# RK3399-AP register map
File version: 1
CPU: CA7 r0p1, little endian, MPU, FPU, I-cache, D-cache, VTOR, 4 interrupt priority bits, 32 interrupts
Registers are 32-bit, read-write, reset 0x0 unless marked. A register's access mark holds for its fields unless they carry their own. Offsets are from the block's base; [hi:lo] are bit positions; {n}, {i} and the like mark numbered series.

## CRU (part 2 of 3)
Base 0xFF760000
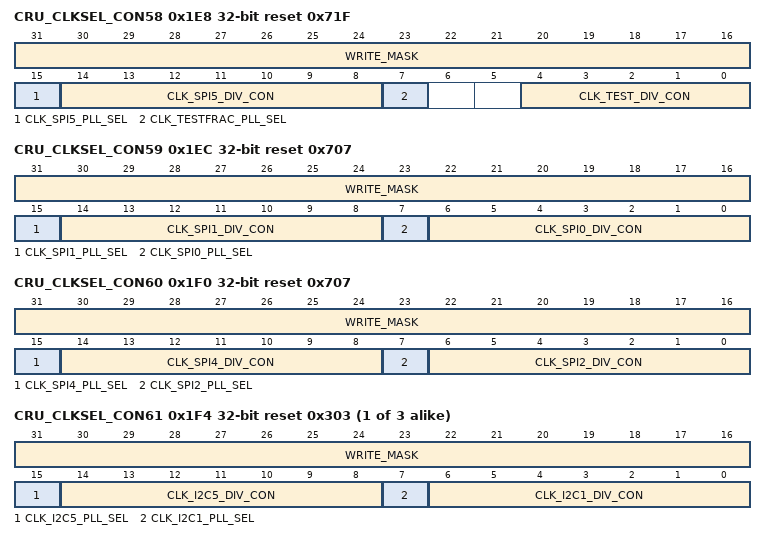
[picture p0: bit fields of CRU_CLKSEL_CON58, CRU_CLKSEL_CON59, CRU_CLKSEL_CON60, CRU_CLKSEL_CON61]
0x1E8 CRU_CLKSEL_CON58 access per field reset 0x71F — Internal clock select and divide register58
  [31:16] WRITE_MASK wo — write mask bits When every bit HIGH, enable the writing corresponding bit When every bit LOW, don't care the writing corresponding bit
  [15] CLK_SPI5_PLL_SEL rw — clk_spi5 clock source select control register 1'b0:CPLL 1'b1:GPLL
  [14:8] CLK_SPI5_DIV_CON rw — spi5 divider control register clk=clk_src/(div_con+1)
  [7] CLK_TESTFRAC_PLL_SEL rw — clk_frac clock source select control register 1'b0:CPLL 1'b1:GPLL
  [4:0] CLK_TEST_DIV_CON rw — test divider control register clk=clk_src/(div_con+1)
0x1EC CRU_CLKSEL_CON59 access per field reset 0x707 — Internal clock select and divide register59
  [31:16] WRITE_MASK wo — write mask bits When every bit HIGH, enable the writing corresponding bit When every bit LOW, don't care the writing corresponding bit
  [15] CLK_SPI1_PLL_SEL rw — clk_spi1 clock source select control register 1'b0:CPLL 1'b1:GPLL
  [14:8] CLK_SPI1_DIV_CON rw — spi1 divider control register clk=clk_src/(div_con+1)
  [7] CLK_SPI0_PLL_SEL rw — clk_spi0 clock source select control register 1'b0:CPLL 1'b1:GPLL
  [6:0] CLK_SPI0_DIV_CON rw — spi0 divider control register clk=clk_src/(div_con+1)
0x1F0 CRU_CLKSEL_CON60 access per field reset 0x707 — Internal clock select and divide register60
  [31:16] WRITE_MASK wo — write mask bits When every bit HIGH, enable the writing corresponding bit When every bit LOW, don't care the writing corresponding bit
  [15] CLK_SPI4_PLL_SEL rw — clk_spi4 clock source select control register 1'b0:CPLL 1'b1:GPLL
  [14:8] CLK_SPI4_DIV_CON rw — spi4 divider control register clk=clk_src/(div_con+1)
  [7] CLK_SPI2_PLL_SEL rw — clk_spi2 clock source select control register 1'b0:CPLL 1'b1:GPLL
  [6:0] CLK_SPI2_DIV_CON rw — spi2 divider control register clk=clk_src/(div_con+1)
{0x100+4i} CRU_CLKSEL_CON{i} access per field reset 0x303 (i=61..63) — Internal clock select and divide register{i}
  [31:16] WRITE_MASK wo — write mask bits When every bit HIGH, enable the writing corresponding bit When every bit LOW, don't care the writing corresponding bit
  [15] CLK_I2C{i-56}_PLL_SEL rw — clk_i2c{i-56} clock source select control register 1'b0:CPLL 1'b1:GPLL
  [14:8] CLK_I2C{i-56}_DIV_CON rw — i2c{i-56} divider control register clk=clk_src/(div_con+1)
  [7] CLK_I2C{i-60}_PLL_SEL rw — clk_i2c{i-60} clock source select control register 1'b0:CPLL 1'b1:GPLL
  [6:0] CLK_I2C{i-60}_DIV_CON rw — i2c{i-60} divider control register clk=clk_src/(div_con+1)
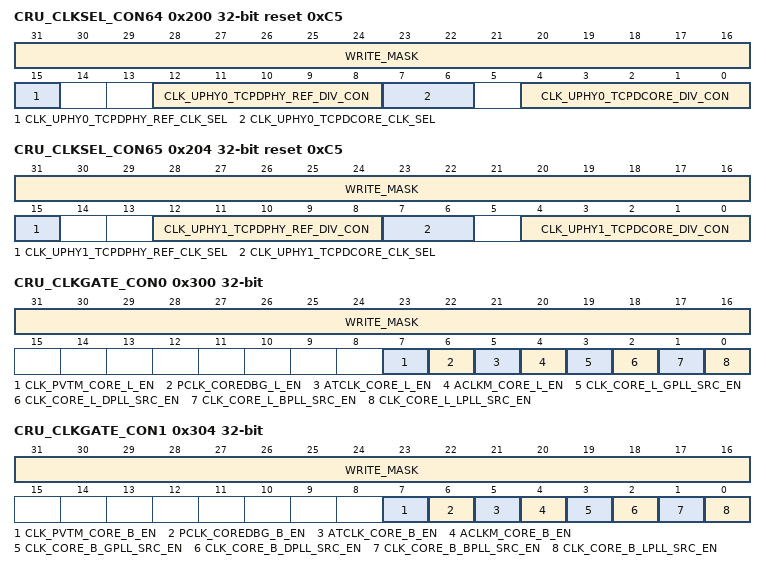
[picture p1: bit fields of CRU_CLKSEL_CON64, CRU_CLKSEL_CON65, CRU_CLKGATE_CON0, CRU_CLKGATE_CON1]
0x200 CRU_CLKSEL_CON64 access per field reset 0xC5 — Internal clock select and divide register64
  [31:16] WRITE_MASK wo — write mask bits When every bit HIGH, enable the writing corresponding bit When every bit LOW, don't care the writing corresponding bit
  [15] CLK_UPHY0_TCPDPHY_REF_CLK_SEL rw — clk_uphy0_tcpdphy_ref clock select control register 1'b0:xin_24m 1'b1:clk_32k
  [12:8] CLK_UPHY0_TCPDPHY_REF_DIV_CON rw — clk_uphy0_tcpdphy_ref divider control register clk=clk_src/(div_con+1)
  [7:6] CLK_UPHY0_TCPDCORE_CLK_SEL rw — clk_uphy0_tcpdcore clock select control register 2'b00:xin_24m 2'b01:clk_32k 2'b10:cpll 2'b11:gpll
  [4:0] CLK_UPHY0_TCPDCORE_DIV_CON rw — clk_uphy0_tcpdcore divider control register clk=clk_src/(div_con+1)
0x204 CRU_CLKSEL_CON65 access per field reset 0xC5 — Internal clock select and divide register65
  [31:16] WRITE_MASK wo — write mask bits When every bit HIGH, enable the writing corresponding bit When every bit LOW, don't care the writing corresponding bit
  [15] CLK_UPHY1_TCPDPHY_REF_CLK_SEL rw — clk_uphy1_tcpdphy_ref clock select control register 1'b0:xin_24m 1'b1:clk_32k
  [12:8] CLK_UPHY1_TCPDPHY_REF_DIV_CON rw — clk_uphy1_tcpdphy_ref divider control register clk=clk_src/(div_con+1)
  [7:6] CLK_UPHY1_TCPDCORE_CLK_SEL rw — clk_uphy1_tcpdcore clock select control register 2'b00:xin_24m 2'b01:clk_32k 2'b10:cpll 2'b11:gpll
  [4:0] CLK_UPHY1_TCPDCORE_DIV_CON rw — clk_uphy1_tcpdcore divider control register clk=clk_src/(div_con+1)
{0x100+4i} CRU_CLKSEL_CON{i} reset 0xBB8EA60 (i=96..98) — Internal clock select and divide register{i-16}
  [31:0] CLK_I2S{i-96}_FRAC_DIV_CON — clk_i2s{i-96}_frac divider control register Fout = Fsrc*numerator/denominator High 16-bit for numerator Low 16-bit for denominator
0x28C CRU_CLKSEL_CON99 reset 0xBB8EA60 — Internal clock select and divide register83
  [31:0] CLK_SPDIF_8CH_FRAC_DIV_CON — spdif_8ch_frac divider control register Fout = Fsrc*numerator/denominator High 16-bit for numerator Low 16-bit for denominator
{0x100+4i} CRU_CLKSEL_CON{i} reset 0xBB8EA60 (i=100..103) — Internal clock select and divide register{i-16}
  [31:0] CLK_UART{i-100}_FRAC_DIV_CON — uart{i-100}_frac divider control register Fout = Fsrc*numerator/denominator High 16-bit for numerator Low 16-bit for denominator
0x2A4 CRU_CLKSEL_CON105 reset 0xBB8EA60 — Internal clock select and divide register89
  [31:0] CLK_TESTFRAC_FRAC_DIV_CON — clk_testfrac frac divider control register Fout = Fsrc*numerator/denominator High 16-bit for numerator Low 16-bit for denominator
0x2A8 CRU_CLKSEL_CON106 reset 0xBB8EA60 — Internal clock select and divide register90
  [31:0] DCLK_VOP0_FRAC_DIV_CON — dclk_vop0_frac divider control register Fout = Fsrc*numerator/denominator High 16-bit for numerator Low 16-bit for denominator
0x2AC CRU_CLKSEL_CON107 reset 0xBB8EA60 — Internal clock select and divide register91
  [31:0] DCLK_VOP1_FRAC_DIV_CON — dclk_vop1_frac divider control register Fout = Fsrc*numerator/denominator High 16-bit for numerator Low 16-bit for denominator
0x300 CRU_CLKGATE_CON0 access per field — Internal clock gating register0
  [31:16] WRITE_MASK wo — write mask bits When every bit HIGH, enable the writing corresponding bit When every bit LOW, don't care the writing corresponding bit
  [7] CLK_PVTM_CORE_L_EN rw — clk_pvtm_core_l clock disable bit When HIGH, disable clock
  [6] PCLK_COREDBG_L_EN rw — pclk_coredbg_l clock disable bit When HIGH, disable clock
  [5] ATCLK_CORE_L_EN rw — atclk_core_l clock disable bit When HIGH, disable clock
  [4] ACLKM_CORE_L_EN rw — aclkm_core_l clock disable bit When HIGH, disable clock
  [3] CLK_CORE_L_GPLL_SRC_EN rw — clk_core_l_gpll clock disable bit When HIGH, disable clock
  [2] CLK_CORE_L_DPLL_SRC_EN rw — clk_core_l_dpll clock disable bit When HIGH, disable clock
  [1] CLK_CORE_L_BPLL_SRC_EN rw — clk_core_l_bpll clock disable bit When HIGH, disable clock
  [0] CLK_CORE_L_LPLL_SRC_EN rw — clk_core_l_lpll clock disable bit When HIGH, disable clock
0x304 CRU_CLKGATE_CON1 access per field — Internal clock gating register1
  [31:16] WRITE_MASK wo — write mask bits When every bit HIGH, enable the writing corresponding bit When every bit LOW, don't care the writing corresponding bit
  [7] CLK_PVTM_CORE_B_EN rw — clk_pvtm_core_b clock disable bit When HIGH, disable clock
  [6] PCLK_COREDBG_B_EN rw — pclk_coredbg_b clock disable bit When HIGH, disable clock
  [5] ATCLK_CORE_B_EN rw — atclk_core_b clock disable bit When HIGH, disable clock
  [4] ACLKM_CORE_B_EN rw — aclkm_core_b clock disable bit When HIGH, disable clock
  [3] CLK_CORE_B_GPLL_SRC_EN rw — clk_core_b_gpll clock disable bit When HIGH, disable clock
  [2] CLK_CORE_B_DPLL_SRC_EN rw — clk_core_b_dpll clock disable bit When HIGH, disable clock
  [1] CLK_CORE_B_BPLL_SRC_EN rw — clk_core_b_bpll clock disable bit When HIGH, disable clock
  [0] CLK_CORE_B_LPLL_SRC_EN rw — clk_core_b_lpll clock disable bit When HIGH, disable clock
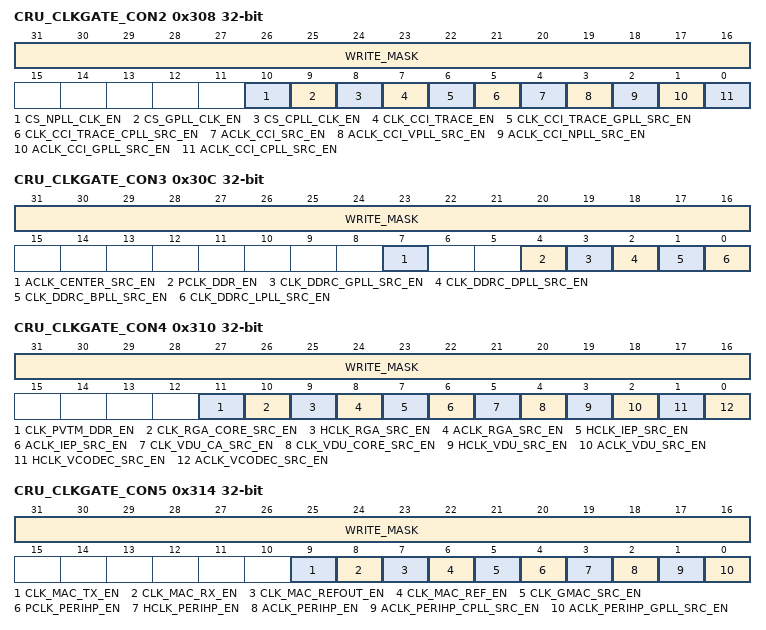
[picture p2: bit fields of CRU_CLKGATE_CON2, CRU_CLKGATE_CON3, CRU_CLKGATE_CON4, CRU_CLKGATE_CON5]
0x308 CRU_CLKGATE_CON2 access per field — Internal clock gating register2
  [31:16] WRITE_MASK wo — write mask bits When every bit HIGH, enable the writing corresponding bit When every bit LOW, don't care the writing corresponding bit
  [10] CS_NPLL_CLK_EN rw — cs_npll_clk clock disable bit When HIGH, disable clock
  [9] CS_GPLL_CLK_EN rw — cs_gpll_clk clock disable bit When HIGH, disable clock
  [8] CS_CPLL_CLK_EN rw — cs_cpll_clk clock disable bit When HIGH, disable clock
  [7] CLK_CCI_TRACE_EN rw — clk_cci_trace clock disable bit When HIGH, disable clock
  [6] CLK_CCI_TRACE_GPLL_SRC_EN rw — clk_cci_trace_gpll clock disable bit When HIGH, disable clock
  [5] CLK_CCI_TRACE_CPLL_SRC_EN rw — clk_cci_trace_cpll clock disable bit When HIGH, disable clock
  [4] ACLK_CCI_SRC_EN rw — aclk_cci_src clock disable bit When HIGH, disable clock
  [3] ACLK_CCI_VPLL_SRC_EN rw — aclk_cci_vpll clock disable bit When HIGH, disable clock
  [2] ACLK_CCI_NPLL_SRC_EN rw — aclk_cci_npll clock disable bit When HIGH, disable clock
  [1] ACLK_CCI_GPLL_SRC_EN rw — aclk_cci_gpll clock disable bit When HIGH, disable clock
  [0] ACLK_CCI_CPLL_SRC_EN rw — aclk_cci_cpll clock disable bit When HIGH, disable clock
0x30C CRU_CLKGATE_CON3 access per field — Internal clock gating register3
  [31:16] WRITE_MASK wo — write mask bits When every bit HIGH, enable the writing corresponding bit When every bit LOW, don't care the writing corresponding bit
  [7] ACLK_CENTER_SRC_EN rw — aclk_center_src clock disable bit When HIGH, disable clock
  [4] PCLK_DDR_EN rw — pclk_ddr clock disable bit When HIGH, disable clock
  [3] CLK_DDRC_GPLL_SRC_EN rw — clk_ddrc_gpll clock disable bit When HIGH, disable clock
  [2] CLK_DDRC_DPLL_SRC_EN rw — clk_ddrc_dpll clock disable bit When HIGH, disable clock
  [1] CLK_DDRC_BPLL_SRC_EN rw — clk_ddrc_bpll clock disable bit When HIGH, disable clock
  [0] CLK_DDRC_LPLL_SRC_EN rw — clk_ddrc_lpll clock disable bit When HIGH, disable clock
0x310 CRU_CLKGATE_CON4 access per field — Internal clock gating register4
  [31:16] WRITE_MASK wo — write mask bits When every bit HIGH, enable the writing corresponding bit When every bit LOW, don't care the writing corresponding bit
  [11] CLK_PVTM_DDR_EN rw — clk_pvtm_ddr clock disable bit When HIGH, disable clock
  [10] CLK_RGA_CORE_SRC_EN rw — clk_rga_core_src clock disable bit When HIGH, disable clock
  [9] HCLK_RGA_SRC_EN rw — hclk_rga_src clock disable bit When HIGH, disable clock
  [8] ACLK_RGA_SRC_EN rw — aclk_rga_src clock disable bit When HIGH, disable clock
  [7] HCLK_IEP_SRC_EN rw — hclk_iep_src clock disable bit When HIGH, disable clock
  [6] ACLK_IEP_SRC_EN rw — aclk_iep_src clock disable bit When HIGH, disable clock
  [5] CLK_VDU_CA_SRC_EN rw — clk_vdu_ca_src clock disable bit When HIGH, disable clock
  [4] CLK_VDU_CORE_SRC_EN rw — clk_vdu_core_src clock disable bit When HIGH, disable clock
  [3] HCLK_VDU_SRC_EN rw — hclk_vdu_src clock disable bit When HIGH, disable clock
  [2] ACLK_VDU_SRC_EN rw — aclk_vdu_src clock disable bit When HIGH, disable clock
  [1] HCLK_VCODEC_SRC_EN rw — hclk_vcodec_src clock disable bit When HIGH, disable clock
  [0] ACLK_VCODEC_SRC_EN rw — aclk_vcodec_src clock disable bit When HIGH, disable clock
0x314 CRU_CLKGATE_CON5 access per field — Internal clock gating register5
  [31:16] WRITE_MASK wo — write mask bits When every bit HIGH, enable the writing corresponding bit When every bit LOW, don't care the writing corresponding bit
  [9] CLK_MAC_TX_EN rw — clk_mac_tx clock disable bit When HIGH, disable clock
  [8] CLK_MAC_RX_EN rw — clk_mac_rx clock disable bit When HIGH, disable clock
  [7] CLK_MAC_REFOUT_EN rw — clk_mac_refout clock disable bit When HIGH, disable clock
  [6] CLK_MAC_REF_EN rw — clk_mac_ref clock disable bit When HIGH, disable clock
  [5] CLK_GMAC_SRC_EN rw — clk_gmac_src clock disable bit When HIGH, disable clock
  [4] PCLK_PERIHP_EN rw — pclk_perihp clock disable bit When HIGH, disable clock
  [3] HCLK_PERIHP_EN rw — hclk_perihp clock disable bit When HIGH, disable clock
  [2] ACLK_PERIHP_EN rw — aclk_perihp clock disable bit When HIGH, disable clock
  [1] ACLK_PERIHP_CPLL_SRC_EN rw — aclk_perihp_cpll clock disable bit When HIGH, disable clock
  [0] ACLK_PERIHP_GPLL_SRC_EN rw — aclk_perihp_gpll clock disable bit When HIGH, disable clock
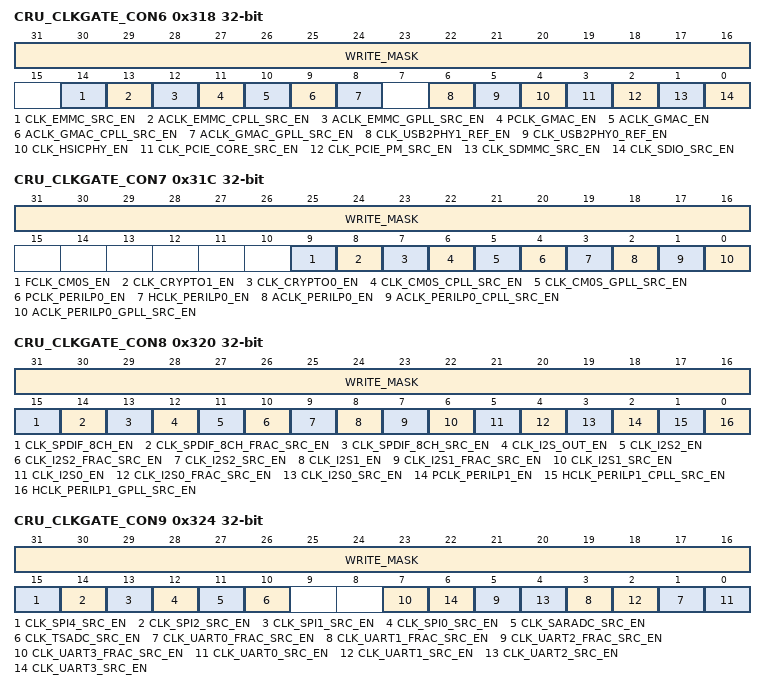
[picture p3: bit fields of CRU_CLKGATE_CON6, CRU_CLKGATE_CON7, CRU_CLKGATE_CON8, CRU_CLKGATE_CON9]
0x318 CRU_CLKGATE_CON6 access per field — Internal clock gating register6
  [31:16] WRITE_MASK wo — write mask bits When every bit HIGH, enable the writing corresponding bit When every bit LOW, don't care the writing corresponding bit
  [14] CLK_EMMC_SRC_EN rw — clk_emmc_src clock disable bit When HIGH, disable clock
  [13] ACLK_EMMC_CPLL_SRC_EN rw — aclk_emmc_cpll clock disable bit When HIGH, disable clock
  [12] ACLK_EMMC_GPLL_SRC_EN rw — aclk_emmc_gpll clock disable bit When HIGH, disable clock
  [11] PCLK_GMAC_EN rw — pclk_gmac clock disable bit When HIGH, disable clock
  [10] ACLK_GMAC_EN rw — aclk_gmac clock disable bit When HIGH, disable clock
  [9] ACLK_GMAC_CPLL_SRC_EN rw — aclk_gmac_cpll clock disable bit When HIGH, disable clock
  [8] ACLK_GMAC_GPLL_SRC_EN rw — aclk_gmac_gpll clock disable bit When HIGH, disable clock
  [6] CLK_USB2PHY1_REF_EN rw — clk_usb2phy1_ref clock disable bit When HIGH, disable clock
  [5] CLK_USB2PHY0_REF_EN rw — clk_usb2phy0_ref clock disable bit When HIGH, disable clock
  [4] CLK_HSICPHY_EN rw — clk_hsicphy clock disable bit When HIGH, disable clock
  [3] CLK_PCIE_CORE_SRC_EN rw — clk_pcie_core_src clock disable bit When HIGH, disable clock
  [2] CLK_PCIE_PM_SRC_EN rw — clk_pcie_pm_src clock disable bit When HIGH, disable clock
  [1] CLK_SDMMC_SRC_EN rw — clk_sdmmc_src clock disable bit When HIGH, disable clock
  [0] CLK_SDIO_SRC_EN rw — clk_sdio_src clock disable bit When HIGH, disable clock
0x31C CRU_CLKGATE_CON7 access per field — Internal clock gating register7
  [31:16] WRITE_MASK wo — write mask bits When every bit HIGH, enable the writing corresponding bit When every bit LOW, don't care the writing corresponding bit
  [9] FCLK_CM0S_EN rw — fclk_cm0s clock disable bit When HIGH, disable clock
  [8] CLK_CRYPTO1_EN rw — clk_crypto1 clock disable bit When HIGH, disable clock
  [7] CLK_CRYPTO0_EN rw — clk_crypto0 clock disable bit When HIGH, disable clock
  [6] CLK_CM0S_CPLL_SRC_EN rw — clk_cm0s_cpll clock disable bit When HIGH, disable clock
  [5] CLK_CM0S_GPLL_SRC_EN rw — clk_cm0s_gpll clock disable bit When HIGH, disable clock
  [4] PCLK_PERILP0_EN rw — pclk_perilp0 clock disable bit When HIGH, disable clock
  [3] HCLK_PERILP0_EN rw — hclk_perilp0 clock disable bit When HIGH, disable clock
  [2] ACLK_PERILP0_EN rw — aclk_perilp0 clock disable bit When HIGH, disable clock
  [1] ACLK_PERILP0_CPLL_SRC_EN rw — aclk_perilp0_cpll clock disable bit When HIGH, disable clock
  [0] ACLK_PERILP0_GPLL_SRC_EN rw — aclk_perilp0_gpll clock disable bit When HIGH, disable clock
0x320 CRU_CLKGATE_CON8 access per field — Internal clock gating register8
  [31:16] WRITE_MASK wo — write mask bits When every bit HIGH, enable the writing corresponding bit When every bit LOW, don't care the writing corresponding bit
  [15] CLK_SPDIF_8CH_EN rw — clk_spdif_8ch clock disable bit When HIGH, disable clock
  [14] CLK_SPDIF_8CH_FRAC_SRC_EN rw — clk_spdif_8ch_frac_src clock disable bit When HIGH, disable clock
  [13] CLK_SPDIF_8CH_SRC_EN rw — clk_spdif_8ch_src clock disable bit When HIGH, disable clock
  [12] CLK_I2S_OUT_EN rw — clk_i2s_out clock disable bit When HIGH, disable clock
  [11] CLK_I2S2_EN rw — clk_i2s2 clock disable bit When HIGH, disable clock
  [10] CLK_I2S2_FRAC_SRC_EN rw — clk_i2s2_frac_src clock disable bit When HIGH, disable clock
  [9] CLK_I2S2_SRC_EN rw — clk_i2s2_src clock disable bit When HIGH, disable clock
  [8] CLK_I2S1_EN rw — clk_i2s1 clock disable bit When HIGH, disable clock
  [7] CLK_I2S1_FRAC_SRC_EN rw — clk_i2s1_frac_src clock disable bit When HIGH, disable clock
  [6] CLK_I2S1_SRC_EN rw — clk_i2s1_src clock disable bit When HIGH, disable clock
  [5] CLK_I2S0_EN rw — clk_i2s0 clock disable bit When HIGH, disable clock
  [4] CLK_I2S0_FRAC_SRC_EN rw — clk_i2s0_frac_src clock disable bit When HIGH, disable clock
  [3] CLK_I2S0_SRC_EN rw — clk_i2s0_src clock disable bit When HIGH, disable clock
  [2] PCLK_PERILP1_EN rw — pclk_perilp1 clock disable bit When HIGH, disable clock
  [1] HCLK_PERILP1_CPLL_SRC_EN rw — hclk_perilp1_cpll clock disable bit When HIGH, disable clock
  [0] HCLK_PERILP1_GPLL_SRC_EN rw — hclk_perilp1_gpll clock disable bit When HIGH, disable clock
0x324 CRU_CLKGATE_CON9 access per field — Internal clock gating register9
  [31:16] WRITE_MASK wo — write mask bits When every bit HIGH, enable the writing corresponding bit When every bit LOW, don't care the writing corresponding bit
  [15] CLK_SPI4_SRC_EN rw — clk_spi4_src clock disable bit When HIGH, disable clock
  [14] CLK_SPI2_SRC_EN rw — clk_spi2_src clock disable bit When HIGH, disable clock
  [13] CLK_SPI1_SRC_EN rw — clk_spi1_src clock disable bit When HIGH, disable clock
  [12] CLK_SPI0_SRC_EN rw — clk_spi0_src clock disable bit When HIGH, disable clock
  [11] CLK_SARADC_SRC_EN rw — clk_saradc_src clock disable bit When HIGH, disable clock
  [10] CLK_TSADC_SRC_EN rw — clk_tsadc_src clock disable bit When HIGH, disable clock
  [2n+1] CLK_UART{n}_FRAC_SRC_EN rw (n=0..3) — clk_uart{n}_frac_src clock disable bit When HIGH, disable clock
  [2n] CLK_UART{n}_SRC_EN rw (n=0..3) — clk_uart{n}_src clock disable bit When HIGH, disable clock
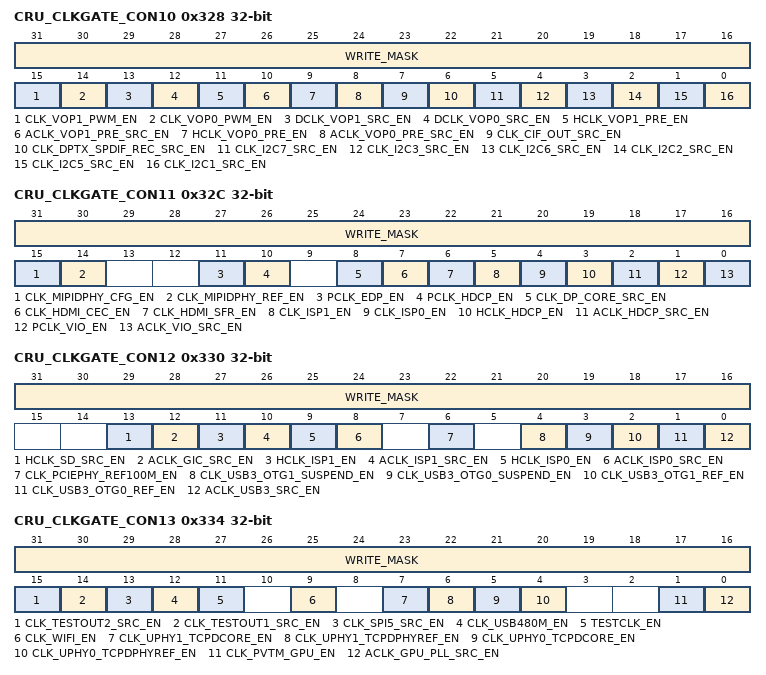
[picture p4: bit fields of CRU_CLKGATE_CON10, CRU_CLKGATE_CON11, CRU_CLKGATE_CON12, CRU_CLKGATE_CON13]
0x328 CRU_CLKGATE_CON10 access per field — Internal clock gating register10
  [31:16] WRITE_MASK wo — write mask bits When every bit HIGH, enable the writing corresponding bit When every bit LOW, don't care the writing corresponding bit
  [15] CLK_VOP1_PWM_EN rw — clk_vop1_pwm clock disable bit When HIGH, disable clock
  [14] CLK_VOP0_PWM_EN rw — clk_vop0_pwm clock disable bit When HIGH, disable clock
  [13] DCLK_VOP1_SRC_EN rw — dclk_vop1_src clock disable bit When HIGH, disable clock
  [12] DCLK_VOP0_SRC_EN rw — dclk_vop0_src clock disable bit When HIGH, disable clock
  [11] HCLK_VOP1_PRE_EN rw — hclk_vop1_pre clock disable bit When HIGH, disable clock
  [10] ACLK_VOP1_PRE_SRC_EN rw — aclk_vop1_pre_src clock disable bit When HIGH, disable clock
  [9] HCLK_VOP0_PRE_EN rw — hclk_vop0_pre clock disable bit When HIGH, disable clock
  [8] ACLK_VOP0_PRE_SRC_EN rw — aclk_vop0_pre_src clock disable bit When HIGH, disable clock
  [7] CLK_CIF_OUT_SRC_EN rw — clk_cif_out_src clock disable bit When HIGH, disable clock
  [6] CLK_DPTX_SPDIF_REC_SRC_EN rw — clk_dptx_spdif_rec_src clock disable bit When HIGH, disable clock
  [5] CLK_I2C7_SRC_EN rw — clk_i2c7_src clock disable bit When HIGH, disable clock
  [4] CLK_I2C3_SRC_EN rw — clk_i2c3_src clock disable bit When HIGH, disable clock
  [3] CLK_I2C6_SRC_EN rw — clk_i2c6_src clock disable bit When HIGH, disable clock
  [2] CLK_I2C2_SRC_EN rw — clk_i2c2_src clock disable bit When HIGH, disable clock
  [1] CLK_I2C5_SRC_EN rw — clk_i2c5_src clock disable bit When HIGH, disable clock
  [0] CLK_I2C1_SRC_EN rw — clk_i2c1_src clock disable bit When HIGH, disable clock
0x32C CRU_CLKGATE_CON11 access per field — Internal clock gating register11
  [31:16] WRITE_MASK wo — write mask bits When every bit HIGH, enable the writing corresponding bit When every bit LOW, don't care the writing corresponding bit
  [15] CLK_MIPIDPHY_CFG_EN rw — clk_mipidphy_cfg clock disable bit When HIGH, disable clock
  [14] CLK_MIPIDPHY_REF_EN rw — clk_mipidphy_ref clock disable bit When HIGH, disable clock
  [11] PCLK_EDP_EN rw — pclk_edp clock disable bit When HIGH, disable clock
  [10] PCLK_HDCP_EN rw — pclk_hdcp clock disable bit When HIGH, disable clock
  [8] CLK_DP_CORE_SRC_EN rw — clk_dp_core_src clock disable bit When HIGH, disable clock
  [7] CLK_HDMI_CEC_EN rw — clk_hdmi_cec clock disable bit When HIGH, disable clock
  [6] CLK_HDMI_SFR_EN rw — clk_hdmi_sfr clock disable bit When HIGH, disable clock
  [5] CLK_ISP1_EN rw — clk_isp1 clock disable bit When HIGH, disable clock
  [4] CLK_ISP0_EN rw — clk_isp0 clock disable bit When HIGH, disable clock
  [3] HCLK_HDCP_EN rw — hclk_hdcp clock disable bit When HIGH, disable clock
  [2] ACLK_HDCP_SRC_EN rw — aclk_hdcp_src clock disable bit When HIGH, disable clock
  [1] PCLK_VIO_EN rw — pclk_vio clock disable bit When HIGH, disable clock
  [0] ACLK_VIO_SRC_EN rw — aclk_vio_src clock disable bit When HIGH, disable clock
0x330 CRU_CLKGATE_CON12 access per field — Internal clock gating register12
  [31:16] WRITE_MASK wo — write mask bits When every bit HIGH, enable the writing corresponding bit When every bit LOW, don't care the writing corresponding bit
  [13] HCLK_SD_SRC_EN rw — hclk_sd_src clock disable bit When HIGH, disable clock
  [12] ACLK_GIC_SRC_EN rw — aclk_gic_src clock disable bit When HIGH, disable clock
  [11] HCLK_ISP1_EN rw — hclk_isp1 clock disable bit When HIGH, disable clock
  [10] ACLK_ISP1_SRC_EN rw — aclk_isp1_src clock disable bit When HIGH, disable clock
  [9] HCLK_ISP0_EN rw — hclk_isp0 clock disable bit When HIGH, disable clock
  [8] ACLK_ISP0_SRC_EN rw — aclk_isp0_src clock disable bit When HIGH, disable clock
  [6] CLK_PCIEPHY_REF100M_EN rw — clk_pciephy_ref100m clock disable bit When HIGH, disable clock
  [4] CLK_USB3_OTG1_SUSPEND_EN rw — clk_usb3_otg1_suspend clock disable bit When HIGH, disable clock
  [3] CLK_USB3_OTG0_SUSPEND_EN rw — clk_usb3_otg0_suspend clock disable bit When HIGH, disable clock
  [2] CLK_USB3_OTG1_REF_EN rw — clk_usb3_otg1_ref clock disable bit When HIGH, disable clock
  [1] CLK_USB3_OTG0_REF_EN rw — clk_usb3_otg0_ref clock disable bit When HIGH, disable clock
  [0] ACLK_USB3_SRC_EN rw — aclk_usb3_src clock disable bit When HIGH, disable clock
0x334 CRU_CLKGATE_CON13 access per field — Internal clock gating register13
  [31:16] WRITE_MASK wo — write mask bits When every bit HIGH, enable the writing corresponding bit When every bit LOW, don't care the writing corresponding bit
  [15] CLK_TESTOUT2_SRC_EN rw — clk_testout2_src clock disable bit When HIGH, disable clock
  [14] CLK_TESTOUT1_SRC_EN rw — clk_testout1_src clock disable bit When HIGH, disable clock
  [13] CLK_SPI5_SRC_EN rw — clk_spi5_src clock disable bit When HIGH, disable clock
  [12] CLK_USB480M_EN rw — clk_usb480m clock disable bit When HIGH, disable clock
  [11] TESTCLK_EN rw — testclk clock disable bit When HIGH, disable clock
  [9] CLK_WIFI_EN rw — clk_wifi clock disable bit When HIGH, disable clock
  [7] CLK_UPHY1_TCPDCORE_EN rw — clk_uphy1_tcpdcore clock disable bit When HIGH, disable clock
  [6] CLK_UPHY1_TCPDPHYREF_EN rw — clk_uphy1_tcpdphyref clock disable bit When HIGH, disable clock
  [5] CLK_UPHY0_TCPDCORE_EN rw — clk_uphy0_tcpdcore clock disable bit When HIGH, disable clock
  [4] CLK_UPHY0_TCPDPHYREF_EN rw — clk_uphy0_tcpdphyref clock disable bit When HIGH, disable clock
  [1] CLK_PVTM_GPU_EN rw — clk_pvtm_gpu clock disable bit When HIGH, disable clock
  [0] ACLK_GPU_PLL_SRC_EN rw — aclk_gpu_pll_src clock disable bit When HIGH, disable clock
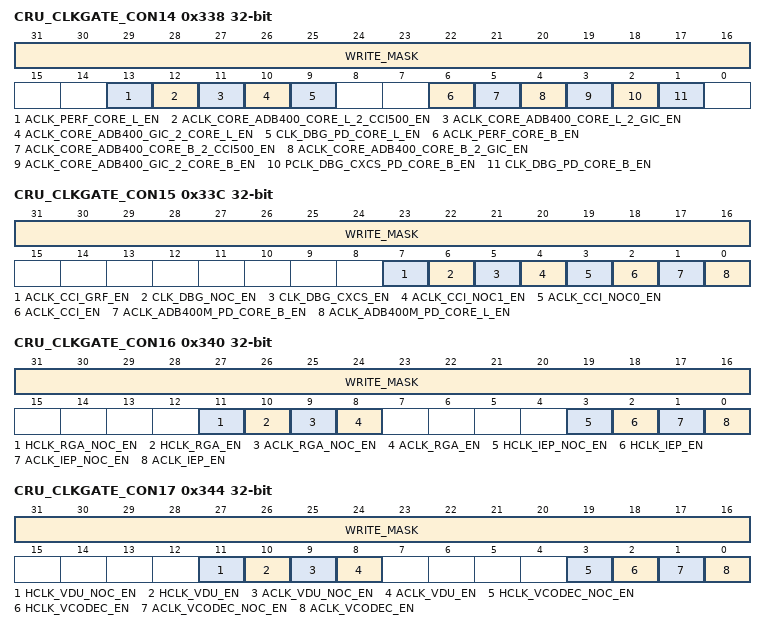
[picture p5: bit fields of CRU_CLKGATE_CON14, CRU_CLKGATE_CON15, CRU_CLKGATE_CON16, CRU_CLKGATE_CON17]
0x338 CRU_CLKGATE_CON14 access per field — Internal clock gating register14
  [31:16] WRITE_MASK wo — write mask bits When every bit HIGH, enable the writing corresponding bit When every bit LOW, don't care the writing corresponding bit
  [13] ACLK_PERF_CORE_L_EN rw — aclk_perf_core_l clock disable bit When HIGH, disable clock
  [12] ACLK_CORE_ADB400_CORE_L_2_CCI500_EN rw — aclk_core_adb400_core_l_2_cci500 clock disable bit When HIGH, disable clock
  [11] ACLK_CORE_ADB400_CORE_L_2_GIC_EN rw — aclk_core_adb400_core_l_2_gic clock disable bit When HIGH, disable clock
  [10] ACLK_CORE_ADB400_GIC_2_CORE_L_EN rw — aclk_core_adb400_gic_2_core_l clock disable bit When HIGH, disable clock
  [9] CLK_DBG_PD_CORE_L_EN rw — clk_dbg_pd_core_l clock disable bit When HIGH, disable clock
  [6] ACLK_PERF_CORE_B_EN rw — aclk_perf_core_b clock disable bit When HIGH, disable clock
  [5] ACLK_CORE_ADB400_CORE_B_2_CCI500_EN rw — aclk_core_adb400_core_b_2_cci500 clock disable bit When HIGH, disable clock
  [4] ACLK_CORE_ADB400_CORE_B_2_GIC_EN rw — aclk_core_adb400_core_b_2_gic clock disable bit When HIGH, disable clock
  [3] ACLK_CORE_ADB400_GIC_2_CORE_B_EN rw — aclk_core_adb400_gic_2_core_b clock disable bit When HIGH, disable clock
  [2] PCLK_DBG_CXCS_PD_CORE_B_EN rw — pclk_dbg_cxcs_pd_core_b clock disable bit When HIGH, disable clock
  [1] CLK_DBG_PD_CORE_B_EN rw — clk_dbg_pd_core_b clock disable bit When HIGH, disable clock
0x33C CRU_CLKGATE_CON15 access per field — Internal clock gating register15
  [31:16] WRITE_MASK wo — write mask bits When every bit HIGH, enable the writing corresponding bit When every bit LOW, don't care the writing corresponding bit
  [7] ACLK_CCI_GRF_EN rw — aclk_cci_grf clock disable bit When HIGH, disable clock Suggest always on
  [6] CLK_DBG_NOC_EN rw — clk_dbg_noc clock disable bit When HIGH, disable clock Suggest always on
  [5] CLK_DBG_CXCS_EN rw — clk_dbg_cxcs clock disable bit When HIGH, disable clock
  [4] ACLK_CCI_NOC1_EN rw — aclk_cci_noc1 clock disable bit When HIGH, disable clock Suggest always on
  [3] ACLK_CCI_NOC0_EN rw — aclk_cci_noc0 clock disable bit When HIGH, disable clock Suggest always on
  [2] ACLK_CCI_EN rw — aclk_cci clock disable bit When HIGH, disable clock
  [1] ACLK_ADB400M_PD_CORE_B_EN rw — aclk_adb400m_pd_core_b clock disable bit When HIGH, disable clock
  [0] ACLK_ADB400M_PD_CORE_L_EN rw — aclk_adb400m_pd_core_l clock disable bit When HIGH, disable clock
0x340 CRU_CLKGATE_CON16 access per field — Internal clock gating register16
  [31:16] WRITE_MASK wo — write mask bits When every bit HIGH, enable the writing corresponding bit When every bit LOW, don't care the writing corresponding bit
  [11] HCLK_RGA_NOC_EN rw — hclk_rga_noc clock disable bit When HIGH, disable clock Suggest always on
  [10] HCLK_RGA_EN rw — hclk_rga clock disable bit When HIGH, disable clock
  [9] ACLK_RGA_NOC_EN rw — aclk_rga_noc clock disable bit When HIGH, disable clock Suggest always on
  [8] ACLK_RGA_EN rw — aclk_rga clock disable bit When HIGH, disable clock
  [3] HCLK_IEP_NOC_EN rw — hclk_iep_noc clock disable bit When HIGH, disable clock Suggest always on
  [2] HCLK_IEP_EN rw — hclk_iep clock disable bit When HIGH, disable clock
  [1] ACLK_IEP_NOC_EN rw — aclk_iep_noc clock disable bit When HIGH, disable clock Suggest always on
  [0] ACLK_IEP_EN rw — aclk_iep clock disable bit When HIGH, disable clock
0x344 CRU_CLKGATE_CON17 access per field — Internal clock gating register17
  [31:16] WRITE_MASK wo — write mask bits When every bit HIGH, enable the writing corresponding bit When every bit LOW, don't care the writing corresponding bit
  [11] HCLK_VDU_NOC_EN rw — hclk_vdu_noc clock disable bit When HIGH, disable clock Suggest always on
  [10] HCLK_VDU_EN rw — hclk_vdu clock disable bit When HIGH, disable clock
  [9] ACLK_VDU_NOC_EN rw — aclk_vdu_noc clock disable bit When HIGH, disable clock Suggest always on
  [8] ACLK_VDU_EN rw — aclk_vdu clock disable bit When HIGH, disable clock
  [3] HCLK_VCODEC_NOC_EN rw — hclk_vcodec_noc clock disable bit When HIGH, disable clock Suggest always on
  [2] HCLK_VCODEC_EN rw — hclk_vcodec clock disable bit When HIGH, disable clock
  [1] ACLK_VCODEC_NOC_EN rw — aclk_vcodec_noc clock disable bit When HIGH, disable clock Suggest always on
  [0] ACLK_VCODEC_EN rw — aclk_vcodec clock disable bit When HIGH, disable clock
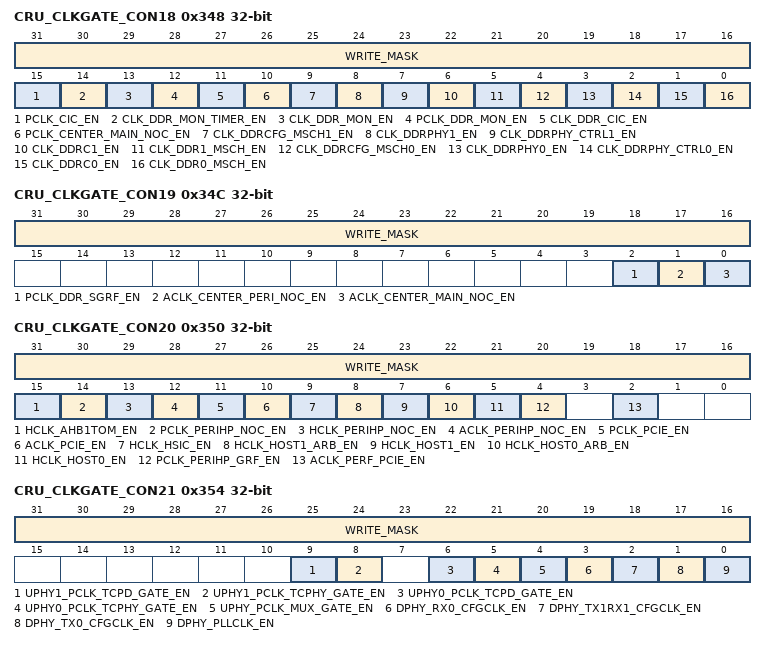
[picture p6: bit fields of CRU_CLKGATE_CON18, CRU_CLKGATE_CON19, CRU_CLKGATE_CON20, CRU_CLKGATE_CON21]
0x348 CRU_CLKGATE_CON18 access per field — Internal clock gating register18
  [31:16] WRITE_MASK wo — write mask bits When every bit HIGH, enable the writing corresponding bit When every bit LOW, don't care the writing corresponding bit
  [15] PCLK_CIC_EN rw — pclk_cic clock disable bit When HIGH, disable clock
  [14] CLK_DDR_MON_TIMER_EN rw — clk_ddr_mon_timer clock disable bit When HIGH, disable clock
  [13] CLK_DDR_MON_EN rw — clk_ddr_mon clock disable bit When HIGH, disable clock
  [12] PCLK_DDR_MON_EN rw — pclk_ddr_mon clock disable bit When HIGH, disable clock
  [11] CLK_DDR_CIC_EN rw — clk_ddr_cic clock disable bit When HIGH, disable clock
  [10] PCLK_CENTER_MAIN_NOC_EN rw — pclk_center_main_noc clock disable bit When HIGH, disable clock Suggest always on
  [9] CLK_DDRCFG_MSCH1_EN rw — clk_ddrcfg_msch1 clock disable bit When HIGH, disable clock
  [8] CLK_DDRPHY1_EN rw — clk_ddrphy1 clock disable bit When HIGH, disable clock
  [7] CLK_DDRPHY_CTRL1_EN rw — clk_ddrphy_ctrl1 clock disable bit When HIGH, disable clock
  [6] CLK_DDRC1_EN rw — clk_ddrc1 clock disable bit When HIGH, disable clock
  [5] CLK_DDR1_MSCH_EN rw — clk_ddr1_msch clock disable bit When HIGH, disable clock
  [4] CLK_DDRCFG_MSCH0_EN rw — clk_ddrcfg_msch0 clock disable bit When HIGH, disable clock
  [3] CLK_DDRPHY0_EN rw — clk_ddrphy0 clock disable bit When HIGH, disable clock
  [2] CLK_DDRPHY_CTRL0_EN rw — clk_ddrphy_ctrl0 clock disable bit When HIGH, disable clock
  [1] CLK_DDRC0_EN rw — clk_ddrc0 clock disable bit When HIGH, disable clock
  [0] CLK_DDR0_MSCH_EN rw — clk_ddr0_msch clock disable bit When HIGH, disable clock
0x34C CRU_CLKGATE_CON19 access per field — Internal clock gating register19
  [31:16] WRITE_MASK wo — write mask bits When every bit HIGH, enable the writing corresponding bit When every bit LOW, don't care the writing corresponding bit
  [2] PCLK_DDR_SGRF_EN rw — pclk_ddr_sgrf clock disable bit When HIGH, disable clock Suggest always on
  [1] ACLK_CENTER_PERI_NOC_EN rw — aclk_center_peri_noc clock disable bit When HIGH, disable clock Suggest always on
  [0] ACLK_CENTER_MAIN_NOC_EN rw — aclk_center_main_noc clock disable bit When HIGH, disable clock Suggest always on
0x350 CRU_CLKGATE_CON20 access per field — Internal clock gating register20
  [31:16] WRITE_MASK wo — write mask bits When every bit HIGH, enable the writing corresponding bit When every bit LOW, don't care the writing corresponding bit
  [15] HCLK_AHB1TOM_EN rw — hclk_ahb1tom clock disable bit When HIGH, disable clock
  [14] PCLK_PERIHP_NOC_EN rw — pclk_perihp_noc clock disable bit When HIGH, disable clock Suggest always on
  [13] HCLK_PERIHP_NOC_EN rw — hclk_perihp_noc clock disable bit When HIGH, disable clock Suggest always on
  [12] ACLK_PERIHP_NOC_EN rw — aclk_perihp_noc clock disable bit When HIGH, disable clock Suggest always on
  [11] PCLK_PCIE_EN rw — pclk_pcie clock disable bit When HIGH, disable clock
  [10] ACLK_PCIE_EN rw — aclk_pcie clock disable bit When HIGH, disable clock
  [9] HCLK_HSIC_EN rw — hclk_hsic clock disable bit When HIGH, disable clock
  [8] HCLK_HOST1_ARB_EN rw — hclk_host1_arb clock disable bit When HIGH, disable clock
  [7] HCLK_HOST1_EN rw — hclk_host1 clock disable bit When HIGH, disable clock
  [6] HCLK_HOST0_ARB_EN rw — hclk_host0_arb clock disable bit When HIGH, disable clock
  [5] HCLK_HOST0_EN rw — hclk_host0 clock disable bit When HIGH, disable clock
  [4] PCLK_PERIHP_GRF_EN rw — pclk_perihp_grf clock disable bit When HIGH, disable clock Suggest always on
  [2] ACLK_PERF_PCIE_EN rw — aclk_perf_pcie clock disable bit When HIGH, disable clock
0x354 CRU_CLKGATE_CON21 access per field — Internal clock gating register21
  [31:16] WRITE_MASK wo — write mask bits When every bit HIGH, enable the writing corresponding bit When every bit LOW, don't care the writing corresponding bit
  [9] UPHY1_PCLK_TCPD_GATE_EN rw — uphy1_pclk_tcpd disable bit When HIGH, disable clock
  [8] UPHY1_PCLK_TCPHY_GATE_EN rw — uphy1_pclk_tcphy clock disable bit When HIGH, disable clock
  [6] UPHY0_PCLK_TCPD_GATE_EN rw — uphy0_pclk_tcpd clock disable bit When HIGH, disable clock
  [5] UPHY0_PCLK_TCPHY_GATE_EN rw — uphy0_pclk_tcphy clock disable bit When HIGH, disable clock
  [4] UPHY_PCLK_MUX_GATE_EN rw — uphy_pclk_mux clock disable bit When HIGH, disable clock
  [3] DPHY_RX0_CFGCLK_EN rw — dphy_rx0_cfg clock disable bit When HIGH, disable clock
  [2] DPHY_TX1RX1_CFGCLK_EN rw — dphy_tx1rx1_cfg clock disable bit When HIGH, disable clock
  [1] DPHY_TX0_CFGCLK_EN rw — dphy_tx0_cfg clock disable bit When HIGH, disable clock
  [0] DPHY_PLLCLK_EN rw — dphy_pll clock disable bit When HIGH, disable clock
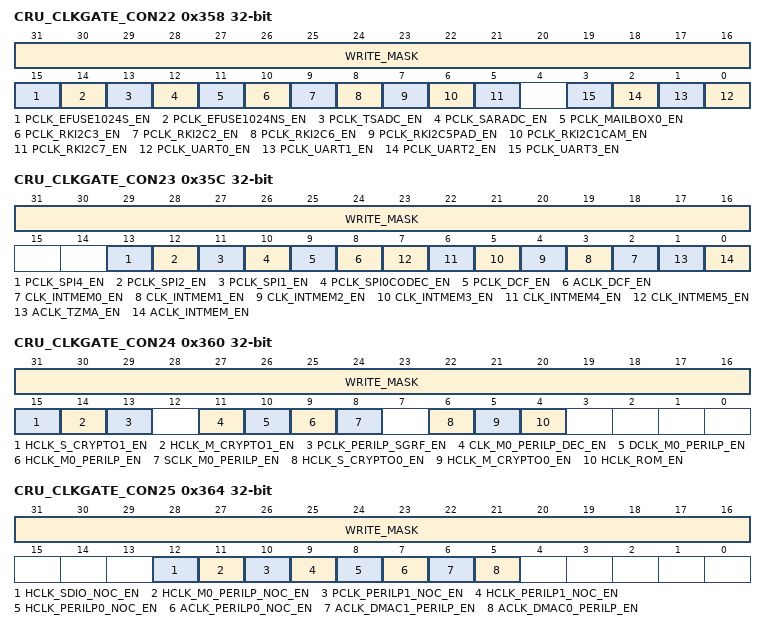
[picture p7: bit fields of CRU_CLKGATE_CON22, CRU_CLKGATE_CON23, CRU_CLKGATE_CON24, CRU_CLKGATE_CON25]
0x358 CRU_CLKGATE_CON22 access per field — Internal clock gating register22
  [31:16] WRITE_MASK wo — write mask bits When every bit HIGH, enable the writing corresponding bit When every bit LOW, don't care the writing corresponding bit
  [15] PCLK_EFUSE1024S_EN rw — pclk_efuse1024s clock disable bit When HIGH, disable clock
  [14] PCLK_EFUSE1024NS_EN rw — pclk_efuse1024ns clock disable bit When HIGH, disable clock
  [13] PCLK_TSADC_EN rw — pclk_tsadc clock disable bit When HIGH, disable clock
  [12] PCLK_SARADC_EN rw — pclk_saradc clock disable bit When HIGH, disable clock
  [11] PCLK_MAILBOX0_EN rw — pclk_mailbox0 clock disable bit When HIGH, disable clock
  [10] PCLK_RKI2C3_EN rw — pclk_rki2c3 clock disable bit When HIGH, disable clock
  [9] PCLK_RKI2C2_EN rw — pclk_rki2c2 clock disable bit When HIGH, disable clock
  [8] PCLK_RKI2C6_EN rw — pclk_rki2c6 clock disable bit When HIGH, disable clock
  [7] PCLK_RKI2C5PAD_EN rw — pclk_rki2c5pad clock disable bit When HIGH, disable clock
  [6] PCLK_RKI2C1CAM_EN rw — pclk_rki2c1cam clock disable bit When HIGH, disable clock
  [5] PCLK_RKI2C7_EN rw — pclk_rki2c7 clock disable bit When HIGH, disable clock
  [n] PCLK_UART{n}_EN rw (n=0..3) — pclk_uart{n} clock disable bit When HIGH, disable clock
0x35C CRU_CLKGATE_CON23 access per field — Internal clock gating register23
  [31:16] WRITE_MASK wo — write mask bits When every bit HIGH, enable the writing corresponding bit When every bit LOW, don't care the writing corresponding bit
  [13] PCLK_SPI4_EN rw — pclk_spi4 clock disable bit When HIGH, disable clock
  [12] PCLK_SPI2_EN rw — pclk_spi2 clock disable bit When HIGH, disable clock
  [11] PCLK_SPI1_EN rw — pclk_spi1 clock disable bit When HIGH, disable clock
  [10] PCLK_SPI0CODEC_EN rw — pclk_spi0codec clock disable bit When HIGH, disable clock
  [9] PCLK_DCF_EN rw — pclk_dcf clock disable bit When HIGH, disable clock
  [8] ACLK_DCF_EN rw — aclk_dcf clock disable bit When HIGH, disable clock
  [n+2] CLK_INTMEM{n}_EN rw (n=0..5) — clk_intmem{n} clock disable bit When HIGH, disable clock
  [1] ACLK_TZMA_EN rw — aclk_tzma clock disable bit When HIGH, disable clock
  [0] ACLK_INTMEM_EN rw — aclk_intmem clock disable bit When HIGH, disable clock
0x360 CRU_CLKGATE_CON24 access per field — Internal clock gating register24
  [31:16] WRITE_MASK wo — write mask bits When every bit HIGH, enable the writing corresponding bit When every bit LOW, don't care the writing corresponding bit
  [15] HCLK_S_CRYPTO1_EN rw — hclk_s_crypto1 clock disable bit When HIGH, disable clock
  [14] HCLK_M_CRYPTO1_EN rw — hclk_m_crypto1 clock disable bit When HIGH, disable clock
  [13] PCLK_PERILP_SGRF_EN rw — pclk_perilp_sgrf clock disable bit When HIGH, disable clock Suggest always on
  [11] CLK_M0_PERILP_DEC_EN rw — clk_m0_perilp_dec clock disable bit When HIGH, disable clock
  [10] DCLK_M0_PERILP_EN rw — dclk_m0_perilp clock disable bit When HIGH, disable clock
  [9] HCLK_M0_PERILP_EN rw — hclk_m0_perilp clock disable bit When HIGH, disable clock
  [8] SCLK_M0_PERILP_EN rw — sclk_m0_perilp clock disable bit When HIGH, disable clock
  [6] HCLK_S_CRYPTO0_EN rw — hclk_s_crypto0 clock disable bit When HIGH, disable clock
  [5] HCLK_M_CRYPTO0_EN rw — hclk_m_crypto0 clock disable bit When HIGH, disable clock
  [4] HCLK_ROM_EN rw — hclk_rom clock disable bit When HIGH, disable clock
0x364 CRU_CLKGATE_CON25 access per field — Internal clock gating register25
  [31:16] WRITE_MASK wo — write mask bits When every bit HIGH, enable the writing corresponding bit When every bit LOW, don't care the writing corresponding bit
  [12] HCLK_SDIO_NOC_EN rw — hclk_sdio_noc clock disable bit When HIGH, disable clock Suggest always on
  [11] HCLK_M0_PERILP_NOC_EN rw — hclk_m0_perilp_noc clock disable bit When HIGH, disable clock Suggest always on
  [10] PCLK_PERILP1_NOC_EN rw — pclk_perilp1_noc clock disable bit When HIGH, disable clock Suggest always on
  [9] HCLK_PERILP1_NOC_EN rw — hclk_perilp1_noc clock disable bit When HIGH, disable clock Suggest always on
  [8] HCLK_PERILP0_NOC_EN rw — hclk_perilp0_noc clock disable bit When HIGH, disable clock Suggest always on
  [7] ACLK_PERILP0_NOC_EN rw — aclk_perilp0_noc clock disable bit When HIGH, disable clock Suggest always on
  [6] ACLK_DMAC1_PERILP_EN rw — aclk_dmac1_perilp clock disable bit When HIGH, disable clock
  [5] ACLK_DMAC0_PERILP_EN rw — aclk_dmac0_perilp clock disable bit When HIGH, disable clock
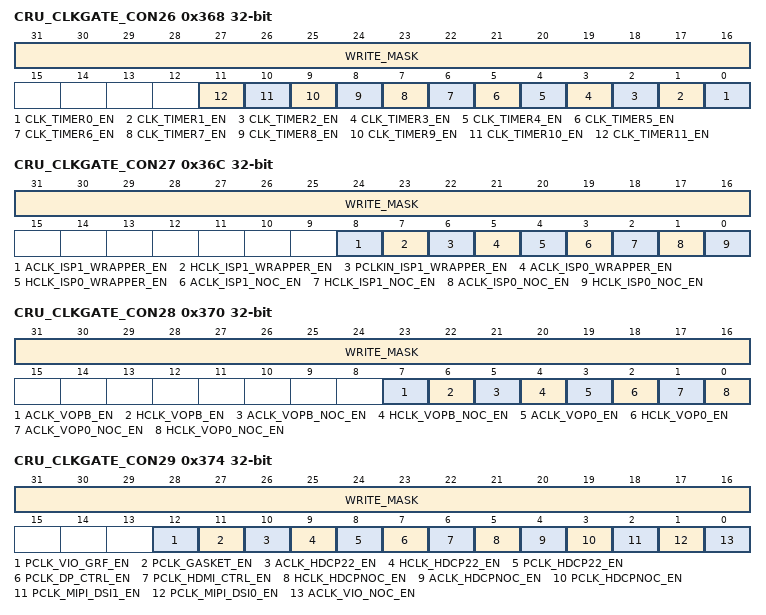
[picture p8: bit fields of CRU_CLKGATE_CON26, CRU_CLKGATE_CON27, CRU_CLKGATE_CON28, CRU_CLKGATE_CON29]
0x368 CRU_CLKGATE_CON26 access per field — Internal clock gating register26
  [31:16] WRITE_MASK wo — write mask bits When every bit HIGH, enable the writing corresponding bit When every bit LOW, don't care the writing corresponding bit
  [n] CLK_TIMER{n}_EN rw (n=0..11) — clk_timer{n} clock disable bit When HIGH, disable clock
0x36C CRU_CLKGATE_CON27 access per field — Internal clock gating register27
  [31:16] WRITE_MASK wo — write mask bits When every bit HIGH, enable the writing corresponding bit When every bit LOW, don't care the writing corresponding bit
  [8] ACLK_ISP1_WRAPPER_EN rw — aclk_isp1_wrapper clock disable bit When HIGH, disable clock
  [7] HCLK_ISP1_WRAPPER_EN rw — hclk_isp1_wrapper clock disable bit When HIGH, disable clock
  [6] PCLKIN_ISP1_WRAPPER_EN rw — pclkin_isp1_wrapper clock disable bit When HIGH, disable clock
  [5] ACLK_ISP0_WRAPPER_EN rw — aclk_isp0_wrapper clock disable bit When HIGH, disable clock
  [4] HCLK_ISP0_WRAPPER_EN rw — hclk_isp0_wrapper clock disable bit When HIGH, disable clock
  [3] ACLK_ISP1_NOC_EN rw — aclk_isp1_noc clock disable bit When HIGH, disable clock Suggest always on
  [2] HCLK_ISP1_NOC_EN rw — hclk_isp1_noc clock disable bit When HIGH, disable clock Suggest always on
  [1] ACLK_ISP0_NOC_EN rw — aclk_isp0_noc clock disable bit When HIGH, disable clock Suggest always on
  [0] HCLK_ISP0_NOC_EN rw — hclk_isp0_noc clock disable bit When HIGH, disable clock Suggest always on
0x370 CRU_CLKGATE_CON28 access per field — Internal clock gating register28
  [31:16] WRITE_MASK wo — write mask bits When every bit HIGH, enable the writing corresponding bit When every bit LOW, don't care the writing corresponding bit
  [7] ACLK_VOPB_EN rw — aclk_vopb clock disable bit When HIGH, disable clock
  [6] HCLK_VOPB_EN rw — hclk_vopb clock disable bit When HIGH, disable clock
  [5] ACLK_VOPB_NOC_EN rw — aclk_vopb_noc clock disable bit When HIGH, disable clock Suggest always on
  [4] HCLK_VOPB_NOC_EN rw — hclk_vopb_noc clock disable bit When HIGH, disable clock Suggest always on
  [3] ACLK_VOP0_EN rw — aclk_vop0 clock disable bit When HIGH, disable clock
  [2] HCLK_VOP0_EN rw — hclk_vop0 clock disable bit When HIGH, disable clock
  [1] ACLK_VOP0_NOC_EN rw — aclk_vop0_noc clock disable bit When HIGH, disable clock Suggest always on
  [0] HCLK_VOP0_NOC_EN rw — hclk_vop0_noc clock disable bit When HIGH, disable clock Suggest always on
0x374 CRU_CLKGATE_CON29 access per field — Internal clock gating register29
  [31:16] WRITE_MASK wo — write mask bits When every bit HIGH, enable the writing corresponding bit When every bit LOW, don't care the writing corresponding bit
  [12] PCLK_VIO_GRF_EN rw — pclk_vio_grf clock disable bit When HIGH, disable clock Suggest always on
  [11] PCLK_GASKET_EN rw — pclk_gasket clock disable bit When HIGH, disable clock
  [10] ACLK_HDCP22_EN rw — aclk_hdcp22 clock disable bit When HIGH, disable clock
  [9] HCLK_HDCP22_EN rw — hclk_hdcp22 clock disable bit When HIGH, disable clock
  [8] PCLK_HDCP22_EN rw — pclk_hdcp22 clock disable bit When HIGH, disable clock
  [7] PCLK_DP_CTRL_EN rw — pclk_dp_ctrl clock disable bit When HIGH, disable clock
  [6] PCLK_HDMI_CTRL_EN rw — pclk_hdmi_ctrl clock disable bit When HIGH, disable clock
  [5] HCLK_HDCPNOC_EN rw — hclk_hdcpnoc clock disable bit When HIGH, disable clock Suggest always on
  [4] ACLK_HDCPNOC_EN rw — aclk_hdcpnoc clock disable bit When HIGH, disable clock Suggest always on
  [3] PCLK_HDCPNOC_EN rw — pclk_hdcpnoc clock disable bit When HIGH, disable clock Suggest always on
  [2] PCLK_MIPI_DSI1_EN rw — pclk_mipi_dsi1 clock disable bit When HIGH, disable clock
  [1] PCLK_MIPI_DSI0_EN rw — pclk_mipi_dsi0 clock disable bit When HIGH, disable clock
  [0] ACLK_VIO_NOC_EN rw — aclk_vio_noc clock disable bit When HIGH, disable clock Suggest always on
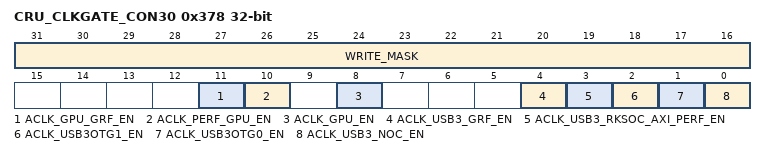
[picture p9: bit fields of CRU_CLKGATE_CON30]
0x378 CRU_CLKGATE_CON30 access per field — Internal clock gating register30
  [31:16] WRITE_MASK wo — write mask bits When every bit HIGH, enable the writing corresponding bit When every bit LOW, don't care the writing corresponding bit
  [11] ACLK_GPU_GRF_EN rw — aclk_gpu_grf clock disable bit When HIGH, disable clock Suggest always on
  [10] ACLK_PERF_GPU_EN rw — aclk_perf_gpu clock disable bit When HIGH, disable clock
  [8] ACLK_GPU_EN rw — aclk_gpu clock disable bit When HIGH, disable clock
  [4] ACLK_USB3_GRF_EN rw — aclk_usb3_grf clock disable bit When HIGH, disable clock Suggest always on
  [3] ACLK_USB3_RKSOC_AXI_PERF_EN rw — aclk_usb3_rksoc_axi_perf clock disable bit When HIGH, disable clock
  [2] ACLK_USB3OTG1_EN rw — aclk_usb3otg1 clock disable bit When HIGH, disable clock
  [1] ACLK_USB3OTG0_EN rw — aclk_usb3otg0 clock disable bit When HIGH, disable clock
  [0] ACLK_USB3_NOC_EN rw — aclk_usb3_noc clock disable bit When HIGH, disable clock Suggest always on
